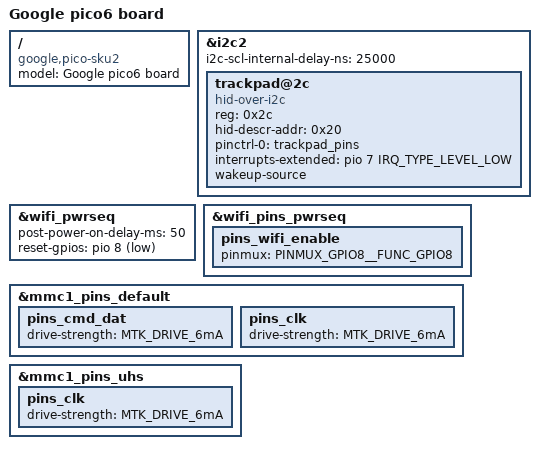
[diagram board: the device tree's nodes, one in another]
// SPDX-License-Identifier: (GPL-2.0 OR MIT)
/*
 * Copyright 2021 Google LLC
 */

/dts-v1/;
#include "mt8183-kukui-icarus.dtsi"
#include "mt8183-kukui-audio-ts3a227e-max98357a.dtsi"

/ {
	model = "Google pico6 board";
	compatible = "google,pico-sku2", "google,pico", "mediatek,mt8183";

};

&i2c2 {
	i2c-scl-internal-delay-ns = <25000>;

	trackpad@2c {
		compatible = "hid-over-i2c";
		reg = <0x2c>;
		hid-descr-addr = <0x20>;

		pinctrl-names = "default";
		pinctrl-0 = <&trackpad_pins>;

		interrupts-extended = <&pio 7 IRQ_TYPE_LEVEL_LOW>;

		wakeup-source;
	};
};

&wifi_pwrseq {
	post-power-on-delay-ms = <50>;

	/* Toggle WIFI_ENABLE to reset the chip. */
	reset-gpios = <&pio 8 1>;
};

&wifi_pins_pwrseq {
	pins_wifi_enable {
		pinmux = <PINMUX_GPIO8__FUNC_GPIO8>;
	};
};

&mmc1_pins_default {
	pins_cmd_dat {
		drive-strength = <MTK_DRIVE_6mA>;
	};
	pins_clk {
		drive-strength = <MTK_DRIVE_6mA>;
	};
};

&mmc1_pins_uhs {
	pins_clk {
		drive-strength = <MTK_DRIVE_6mA>;
	};
};

/delete-node/ &bluetooth;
